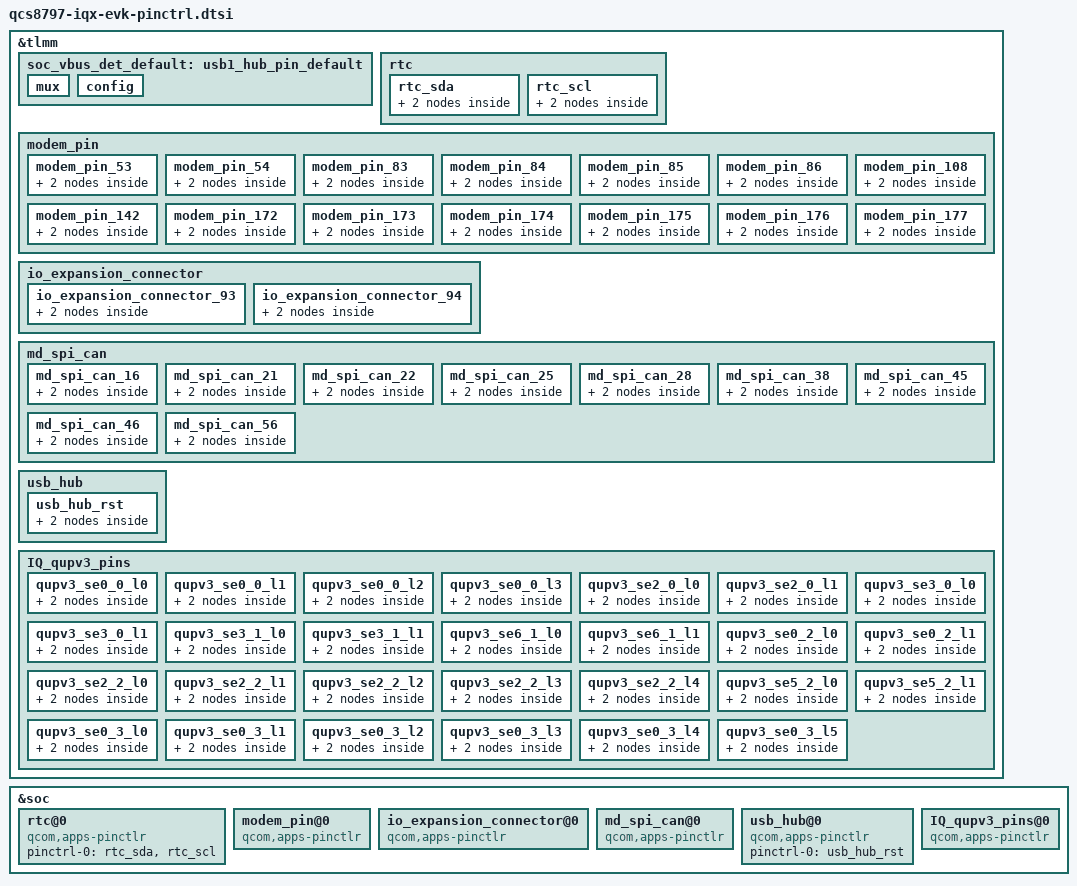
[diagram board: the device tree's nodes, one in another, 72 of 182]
// SPDX-License-Identifier: BSD-3-Clause
/*
 * Copyright (c) Qualcomm Technologies, Inc. and/or its subsidiaries.
 */

&tlmm {
	soc_vbus_det_default: usb1_hub_pin_default {
		mux {
			pins = "gpio169";
			function = "gpio";
		};
		config {
			pins = "gpio169";
			drive-strength = <2>;    /* 2 mA */
			bias-pull-up;             /* PULL UP */
			output-high;
		};
	};
	rtc: rtc {
		rtc_sda: rtc_sda {
			mux {
				pins = "gpio123";
				function = "gpio";
			};
			config {
				pins = "gpio123";
				drive-strength = <2>;   /* 2 mA */
				bias-disable;           /* External pull-ups */
			};
		};
		rtc_scl: rtc_scl {
			mux {
				pins = "gpio124";
				function = "gpio";
			};
			config {
				pins = "gpio124";
				drive-strength = <2>;   /* 2 mA */
				bias-disable;           /* External pull-ups */
			};
		};
	};
	modem_pin: modem_pin {
		modem_pin_53: modem_pin_53 {
			mux {
				pins = "gpio53";
				function = "gpio";
			};
			config {
				pins = "gpio53";
				drive-strength = <2>;   /* 2 mA */
				bias-pull-down;         /* PULL DOWN */
				input-enable;
			};
		};
		modem_pin_54: modem_pin_54 {
			mux {
				pins = "gpio54";
				function = "gpio";
			};
			config {
				pins = "gpio54";
				drive-strength = <2>;   /* 2 mA */
				bias-pull-down;         /* PULL DOWN */
				input-enable;
			};
		};
		modem_pin_83: modem_pin_83 {
			mux {
				pins = "gpio83";
				function = "gpio";
			};
			config {
				pins = "gpio83";
				drive-strength = <2>;   /* 2 mA */
				bias-pull-down;         /* PULL DOWN */
				input-enable;
			};
		};
		modem_pin_84: modem_pin_84 {
			mux {
				pins = "gpio84";
				function = "gpio";
			};
			config {
				pins = "gpio84";
				drive-strength = <2>;   /* 2 mA */
				bias-pull-down;         /* PULL DOWN */
				input-enable;
			};
		};
		modem_pin_85: modem_pin_85 {
			mux {
				pins = "gpio85";
				function = "gpio";
			};
			config {
				pins = "gpio85";
				drive-strength = <2>;   /* 2 mA */
				bias-pull-down;         /* PULL DOWN */
				input-enable;
			};
		};
		modem_pin_86: modem_pin_86 {
			mux {
				pins = "gpio86";
				function = "gpio";
			};
			config {
				pins = "gpio86";
				drive-strength = <2>;   /* 2 mA */
				bias-pull-down;         /* PULL DOWN */
				input-enable;
			};
		};
		modem_pin_108: modem_pin_108 {
			mux {
				pins = "gpio108";
				function = "gpio";
			};
			config {
				pins = "gpio108";
				drive-strength = <2>;   /* 2 mA */
				bias-pull-down;         /* PULL DOWN */
				input-enable;
			};
		};
		modem_pin_142: modem_pin_142 {
			mux {
				pins = "gpio142";
				function = "gpio";
			};
			config {
				pins = "gpio142";
				drive-strength = <2>;   /* 2 mA */
				bias-pull-down;         /* PULL DOWN */
				input-enable;
			};
		};
		modem_pin_172: modem_pin_172 {
			mux {
				pins = "gpio172";
				function = "gpio";
			};
			config {
				pins = "gpio172";
				drive-strength = <2>;   /* 2 mA */
				bias-pull-down;         /* PULL DOWN */
				input-enable;
			};
		};
		modem_pin_173: modem_pin_173 {
			mux {
				pins = "gpio173";
				function = "gpio";
			};
			config {
				pins = "gpio173";
				drive-strength = <2>;   /* 2 mA */
				bias-pull-down;         /* PULL DOWN */
				input-enable;
			};
		};
		modem_pin_174: modem_pin_174 {
			mux {
				pins = "gpio174";
				function = "gpio";
			};
			config {
				pins = "gpio174";
				drive-strength = <2>;   /* 2 mA */
				bias-pull-down;         /* PULL DOWN */
				input-enable;
			};
		};
		modem_pin_175: modem_pin_175 {
			mux {
				pins = "gpio175";
				function = "gpio";
			};
			config {
				pins = "gpio175";
				drive-strength = <2>;   /* 2 mA */
				bias-pull-down;         /* PULL DOWN */
				input-enable;
			};
		};
		modem_pin_176: modem_pin_176 {
			mux {
				pins = "gpio176";
				function = "gpio";
			};
			config {
				pins = "gpio176";
				drive-strength = <2>;   /* 2 mA */
				bias-pull-down;         /* PULL DOWN */
				input-enable;
			};
		};
		modem_pin_177: modem_pin_177 {
			mux {
				pins = "gpio177";
				function = "gpio";
			};
			config {
				pins = "gpio177";
				drive-strength = <2>;   /* 2 mA */
				bias-pull-down;         /* PULL DOWN */
				input-enable;
			};
		};
	};
	io_expansion_connector: io_expansion_connector {
		io_expansion_connector_93: io_expansion_connector_93 {
			mux {
				pins = "gpio93";
				function = "gpio";
			};
			config {
				pins = "gpio93";
				drive-strength = <2>;   /* 2 mA */
				bias-pull-down;         /* PULL DOWN */
				input-enable;
			};
		};
		io_expansion_connector_94: io_expansion_connector_94 {
			mux {
				pins = "gpio94";
				function = "gpio";
			};
			config {
				pins = "gpio94";
				drive-strength = <2>;   /* 2 mA */
				bias-pull-down;         /* PULL DOWN */
				input-enable;
			};
		};
	};

	md_spi_can: md_spi_can {
		md_spi_can_16: md_spi_can_16 {
			mux {
				pins = "gpio16";
				function = "gpio";
			};
			config {
				pins = "gpio16";
				drive-strength = <2>;   /* 2 mA */
				bias-pull-down;         /* PULL DOWN */
				input-enable;
			};
		};
		md_spi_can_21: md_spi_can_21 {
			mux {
				pins = "gpio21";
				function = "gpio";
			};
			config {
				pins = "gpio21";
				drive-strength = <2>;   /* 2 mA */
				bias-pull-down;         /* PULL DOWN */
				input-enable;
			};
		};
		md_spi_can_22: md_spi_can_22 {
			mux {
				pins = "gpio22";
				function = "gpio";
			};
			config {
				pins = "gpio22";
				drive-strength = <2>;   /* 2 mA */
				bias-pull-down;         /* PULL DOWN */
				input-enable;
			};
		};
		md_spi_can_25: md_spi_can_25 {
			mux {
				pins = "gpio25";
				function = "gpio";
			};
			config {
				pins = "gpio25";
				drive-strength = <2>;   /* 2 mA */
				bias-pull-down;         /* PULL DOWN */
				input-enable;
			};
		};
		md_spi_can_28: md_spi_can_28 {
			mux {
				pins = "gpio28";
				function = "gpio";
			};
			config {
				pins = "gpio28";
				drive-strength = <2>;   /* 2 mA */
				bias-pull-down;         /* PULL DOWN */
				input-enable;
			};
		};
		md_spi_can_38: md_spi_can_38 {
			mux {
				pins = "gpio38";
				function = "gpio";
			};
			config {
				pins = "gpio38";
				drive-strength = <2>;   /* 2 mA */
				bias-pull-down;         /* PULL DOWN */
				input-enable;
			};
		};
		md_spi_can_45: md_spi_can_45 {
			mux {
				pins = "gpio45";
				function = "gpio";
			};
			config {
				pins = "gpio45";
				drive-strength = <2>;   /* 2 mA */
				bias-pull-down;         /* PULL DOWN */
				input-enable;
			};
		};
		md_spi_can_46: md_spi_can_46 {
			mux {
				pins = "gpio46";
				function = "gpio";
			};
			config {
				pins = "gpio46";
				drive-strength = <2>;   /* 2 mA */
				bias-pull-down;         /* PULL DOWN */
				input-enable;
			};
		};
		md_spi_can_56: md_spi_can_56 {
			mux {
				pins = "gpio56";
				function = "gpio";
			};
			config {
				pins = "gpio56";
				drive-strength = <2>;   /* 2 mA */
				bias-pull-down;         /* PULL DOWN */
				input-enable;
			};
		};
	};

	usb_hub: usb_hub {
		usb_hub_rst: usb_hub_rst {
			mux {
				pins = "gpio170";
				function = "gpio";
			};
			config {
				pins = "gpio170";
				drive-strength = <2>;   /* 2 mA */
				bias-disable;
				output-high;
			};
		};
	};

	IQ_qupv3_pins: IQ_qupv3_pins {
		qupv3_se0_0_l0: qupv3_se0_0_l0 {
			mux {
				pins = "gpio111";
				function = "qup0_se0_l0";
			};

			config {
				pins = "gpio111";
				drive-strength = <2>;
				bias-disable;
			};
		};
		qupv3_se0_0_l1: qupv3_se0_0_l1 {
			mux {
				pins = "gpio112";
				function = "qup0_se0_l1";
			};

			config {
				pins = "gpio112";
				drive-strength = <2>;
				bias-disable;
			};
		};
		qupv3_se0_0_l2: qupv3_se0_0_l2 {
			mux {
				pins = "gpio109";
				function = "qup0_se0_l2";
			};

			config {
				pins = "gpio109";
				drive-strength = <2>;
				bias-disable;
			};
		};
		qupv3_se0_0_l3: qupv3_se0_0_l3 {
			mux {
				pins = "gpio110";
				function = "qup0_se0_l3";
			};

			config {
				pins = "gpio110";
				drive-strength = <2>;
				bias-disable;
			};
		};

		qupv3_se2_0_l0: qupv3_se2_0_l0 {
			mux {
				pins = "gpio113";
				function = "qup0_se2_l0";
			};

			config {
				pins = "gpio113";
				drive-strength = <2>;
				bias-disable;
			};
		};
		qupv3_se2_0_l1: qupv3_se2_0_l1 {
			mux {
				pins = "gpio114";
				function = "qup0_se2_l1";
			};

			config {
				pins = "gpio114";
				drive-strength = <2>;
				bias-disable;
			};
		};

		qupv3_se3_0_l0: qupv3_se3_0_l0 {
			mux {
				pins = "gpio115";
				function = "qup0_se3_l0";
			};

			config {
				pins = "gpio115";
				drive-strength = <2>;
				bias-disable;
			};
		};
		qupv3_se3_0_l1: qupv3_se3_0_l1 {
			mux {
				pins = "gpio116";
				function = "qup0_se3_l1";
			};

			config {
				pins = "gpio116";
				drive-strength = <2>;
				bias-disable;
			};
		};

		qupv3_se3_1_l0: qupv3_se3_1_l0 {
			mux {
				pins = "gpio129";
				function = "qup1_se3_l0";
			};

			config {
				pins = "gpio129";
				drive-strength = <2>;
				bias-disable;
			};
		};
		qupv3_se3_1_l1: qupv3_se3_1_l1 {
			mux {
				pins = "gpio130";
				function = "qup1_se3_l1";
			};

			config {
				pins = "gpio130";
				drive-strength = <2>;
				bias-disable;
			};
		};

		qupv3_se6_1_l0: qupv3_se6_1_l0 {
			mux {
				pins = "gpio137";
				function = "qup1_se6_l0";
			};

			config {
				pins = "gpio137";
				drive-strength = <2>;
				bias-disable;
			};
		};
		qupv3_se6_1_l1: qupv3_se6_1_l1 {
			mux {
				pins = "gpio138";
				function = "qup1_se6_l1";
			};

			config {
				pins = "gpio138";
				drive-strength = <2>;
				bias-disable;
			};
		};

		qupv3_se0_2_l0: qupv3_se0_2_l0 {
			mux {
				pins = "gpio139";
				function = "qup2_se0_l0";
			};

			config {
				pins = "gpio139";
				drive-strength = <2>;
				bias-disable;
			};
		};
		qupv3_se0_2_l1: qupv3_se0_2_l1 {
			mux {
				pins = "gpio140";
				function = "qup2_se0_l1";
			};

			config {
				pins = "gpio140";
				drive-strength = <2>;
				bias-disable;
			};
		};

		qupv3_se2_2_l0: qupv3_se2_2_l0 {
			mux {
				pins = "gpio145";
				function = "qup2_se2_l0";
			};

			config {
				pins = "gpio145";
				drive-strength = <2>;
				bias-disable;
			};
		};
		qupv3_se2_2_l1: qupv3_se2_2_l1 {
			mux {
				pins = "gpio146";
				function = "qup2_se2_l1";
			};

			config {
				pins = "gpio146";
				drive-strength = <2>;
				bias-disable;
			};
		};
		qupv3_se2_2_l2: qupv3_se2_2_l2 {
			mux {
				pins = "gpio147";
				function = "qup2_se2_l2";
			};

			config {
				pins = "gpio147";
				drive-strength = <2>;
				bias-disable;
			};
		};
		qupv3_se2_2_l3: qupv3_se2_2_l3 {
			mux {
				pins = "gpio148";
				function = "qup2_se2_l3";
			};

			config {
				pins = "gpio148";
				drive-strength = <2>;
				bias-disable;
			};
		};
		qupv3_se2_2_l4: qupv3_se2_2_l4 {
			mux {
				pins = "gpio149";
				function = "qup2_se2_l4";
			};

			config {
				pins = "gpio149";
				drive-strength = <2>;
				bias-disable;
			};
		};


		qupv3_se5_2_l0: qupv3_se5_2_l0 {
			mux {
				pins = "gpio156";
				function = "qup2_se5_l0";
			};

			config {
				pins = "gpio156";
				drive-strength = <2>;
				bias-disable;
			};
		};
		qupv3_se5_2_l1: qupv3_se5_2_l1 {
			mux {
				pins = "gpio157";
				function = "qup2_se5_l1";
			};

			config {
				pins = "gpio157";
				drive-strength = <2>;
				bias-disable;
			};
		};

		qupv3_se0_3_l0: qupv3_se0_3_l0 {
			mux {
				pins = "gpio102";
				function = "qup3_se0_l0";
			};

			config {
				pins = "gpio102";
				drive-strength = <2>;
				bias-disable;
			};
		};
		qupv3_se0_3_l1: qupv3_se0_3_l1 {
			mux {
				pins = "gpio103";
				function = "qup3_se0_l1";
			};

			config {
				pins = "gpio103";
				drive-strength = <2>;
				bias-disable;
			};
		};
		qupv3_se0_3_l2: qupv3_se0_3_l2 {
			mux {
				pins = "gpio104";
				function = "qup3_se0_l2";
			};

			config {
				pins = "gpio104";
				drive-strength = <2>;
				bias-disable;
			};
		};
		qupv3_se0_3_l3: qupv3_se0_3_l3 {
			mux {
				pins = "gpio105";
				function = "qup3_se0_l3";
			};

			config {
				pins = "gpio105";
				drive-strength = <2>;
				bias-disable;
			};
		};
		qupv3_se0_3_l4: qupv3_se0_3_l4 {
			mux {
				pins = "gpio106";
				function = "qup3_se0_l4";
			};

			config {
				pins = "gpio106";
				drive-strength = <2>;
				bias-disable;
			};
		};
		qupv3_se0_3_l5: qupv3_se0_3_l5 {
			mux {
				pins = "gpio107";
				function = "qup3_se0_l5";
			};

			config {
				pins = "gpio107";
				drive-strength = <2>;
				bias-disable;
			};
		};
	};
};

&soc {
	rtc@0 {
		compatible = "qcom,apps-pinctlr";
		pinctrl-names = "default";
		pinctrl-0 = <&rtc_sda &rtc_scl>;
	};
	modem_pin@0 {
		compatible = "qcom,apps-pinctlr";
		pinctrl-names = "default";
		pinctrl-0 = <&modem_pin_53 &modem_pin_54
					&modem_pin_83 &modem_pin_84
					&modem_pin_85 &modem_pin_86
					&modem_pin_108 &modem_pin_142
					&modem_pin_172 &modem_pin_173
					&modem_pin_174 &modem_pin_175
					&modem_pin_176 &modem_pin_177>;
	};
	io_expansion_connector@0 {
		compatible = "qcom,apps-pinctlr";
		pinctrl-names = "default";
		pinctrl-0 = <&io_expansion_connector_93 &io_expansion_connector_94>;
	};
	md_spi_can@0 {
		compatible = "qcom,apps-pinctlr";
		pinctrl-names = "default";
		pinctrl-0 = <&md_spi_can_16 &md_spi_can_21
					&md_spi_can_22 &md_spi_can_25
					&md_spi_can_28 &md_spi_can_38
					&md_spi_can_45 &md_spi_can_46
					&md_spi_can_56>;
	};

	usb_hub@0 {
		compatible = "qcom,apps-pinctlr";
		pinctrl-names = "default";
		pinctrl-0 = <&usb_hub_rst>;
	};

	IQ_qupv3_pins@0 {
		compatible = "qcom,apps-pinctlr";
		pinctrl-names = "default";
		pinctrl-0 = <&qupv3_se0_0_l0 &qupv3_se0_0_l1
					&qupv3_se0_0_l2 &qupv3_se0_0_l3
					&qupv3_se2_0_l0 &qupv3_se2_0_l1
					&qupv3_se3_0_l0 &qupv3_se3_0_l1
					&qupv3_se6_1_l0 &qupv3_se6_1_l1
					&qupv3_se0_2_l0 &qupv3_se0_2_l1
					&qupv3_se2_2_l0 &qupv3_se2_2_l1
					&qupv3_se2_2_l2 &qupv3_se2_2_l3
					&qupv3_se2_2_l4 &qupv3_se5_2_l0
					&qupv3_se5_2_l1 &qupv3_se0_3_l0
					&qupv3_se0_3_l1 &qupv3_se0_3_l2
					&qupv3_se0_3_l3 &qupv3_se0_3_l4
					&qupv3_se0_3_l5>;
	};
};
